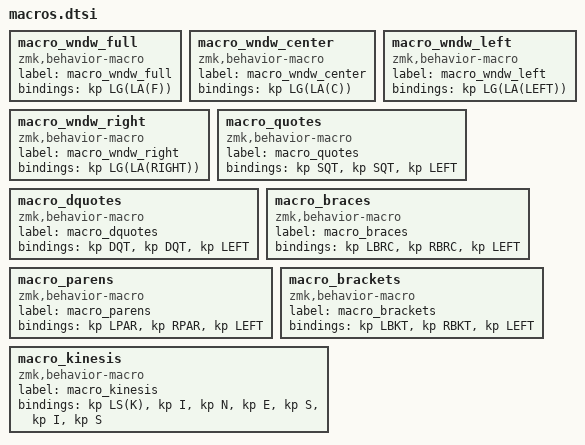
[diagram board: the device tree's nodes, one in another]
macro_wndw_full: macro_wndw_full{
compatible = "zmk,behavior-macro";
label = "macro_wndw_full";
#binding-cells = <0>;
bindings = <&kp LG(LA(F))>;
};
macro_wndw_center: macro_wndw_center{
compatible = "zmk,behavior-macro";
label = "macro_wndw_center";
#binding-cells = <0>;
bindings = <&kp LG(LA(C))>;
};
macro_wndw_left: macro_wndw_left{
compatible = "zmk,behavior-macro";
label = "macro_wndw_left";
#binding-cells = <0>;
bindings = <&kp LG(LA(LEFT))>;
};
macro_wndw_right: macro_wndw_right{
compatible = "zmk,behavior-macro";
label = "macro_wndw_right";
#binding-cells = <0>;
bindings = <&kp LG(LA(RIGHT))>;
};
macro_quotes: macro_quotes{
compatible = "zmk,behavior-macro";
label = "macro_quotes";
#binding-cells = <0>;
bindings = <&kp SQT>, <&kp SQT>, <&kp LEFT>;
};
macro_dquotes: macro_dquotes{
compatible = "zmk,behavior-macro";
label = "macro_dquotes";
#binding-cells = <0>;
bindings = <&kp DQT>, <&kp DQT>, <&kp LEFT>;
};
macro_braces: macro_braces{
compatible = "zmk,behavior-macro";
label = "macro_braces";
#binding-cells = <0>;
bindings = <&kp LBRC>, <&kp RBRC>, <&kp LEFT>;
};
macro_parens: macro_parens{
compatible = "zmk,behavior-macro";
label = "macro_parens";
#binding-cells = <0>;
bindings = <&kp LPAR>, <&kp RPAR>, <&kp LEFT>;
};
macro_brackets: macro_brackets{
compatible = "zmk,behavior-macro";
label = "macro_brackets";
#binding-cells = <0>;
bindings = <&kp LBKT>, <&kp RBKT>, <&kp LEFT>;
};
macro_kinesis: macro_kinesis{
compatible = "zmk,behavior-macro";
label = "macro_kinesis";
#binding-cells = <0>;
bindings = <&kp LS(K)>, <&kp I>, <&kp N>, <&kp E>, <&kp S>, <&kp I>, <&kp S>;
};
